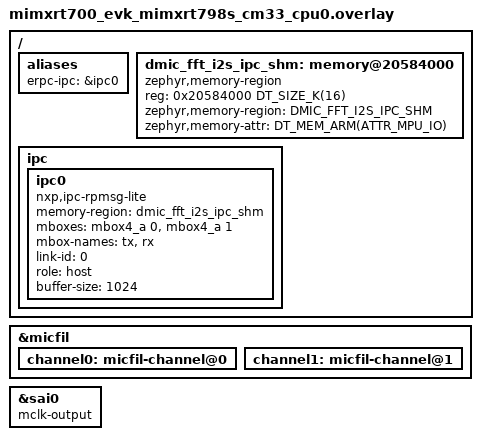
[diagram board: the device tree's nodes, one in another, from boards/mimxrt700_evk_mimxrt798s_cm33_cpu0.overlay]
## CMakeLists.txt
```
# Copyright 2026 NXP
# SPDX-License-Identifier: Apache-2.0

cmake_minimum_required(VERSION 3.20.0)

find_package(Zephyr REQUIRED HINTS $ENV{ZEPHYR_BASE})
project(mpipe_dmic_fft_i2s)

# The HiFi4 computes gain, FFT and IFFT; this core captures and plays back
target_sources(app PRIVATE src/main.c)

include(${CMAKE_CURRENT_LIST_DIR}/dmic_fft_i2s.cmake)

# Boot and image embedding of the HiFi4: the loader of the RTxxx AMP samples
# (dsp.c, dspimgs.S). dspimgs.S includes the reset, text and data sections of
# the HiFi4 image, which are either the prebuilt binaries that sysbuild.cmake
# selected, or the ones of the sysbuild image "remote".
set(RTXXX_DSP_COMMON ${ZEPHYR_BASE}/samples/boards/nxp/adsp/rtxxx/common)

target_sources(app PRIVATE ${RTXXX_DSP_COMMON}/src/dsp.c ${RTXXX_DSP_COMMON}/src/dspimgs.S)
include_directories(${RTXXX_DSP_COMMON}/src)

zephyr_get(HIFI4_BIN_RESET SYSBUILD GLOBAL)
zephyr_get(HIFI4_BIN_TEXT SYSBUILD GLOBAL)
zephyr_get(HIFI4_BIN_DATA SYSBUILD GLOBAL)

if(DEFINED HIFI4_BIN_RESET AND DEFINED HIFI4_BIN_TEXT AND DEFINED HIFI4_BIN_DATA)
  set(hifi4_bin_depends ${HIFI4_BIN_RESET} ${HIFI4_BIN_TEXT} ${HIFI4_BIN_DATA})
else()
  set(hifi4_build_dir ${CMAKE_CURRENT_BINARY_DIR}/../remote/zephyr)
  set(HIFI4_BIN_RESET ${hifi4_build_dir}/zephyr.reset.bin)
  set(HIFI4_BIN_TEXT ${hifi4_build_dir}/zephyr.text.bin)
  set(HIFI4_BIN_DATA ${hifi4_build_dir}/zephyr.data.bin)
  set(hifi4_bin_depends ${hifi4_build_dir}/zephyr.elf)
endif()

set(hifi4_bin_syms
  "HIFI4_BIN_RESET=\"${HIFI4_BIN_RESET}\""
  "HIFI4_BIN_TEXT=\"${HIFI4_BIN_TEXT}\""
  "HIFI4_BIN_DATA=\"${HIFI4_BIN_DATA}\""
)

set_source_files_properties(
  ${RTXXX_DSP_COMMON}/src/dspimgs.S
  PROPERTIES
  COMPILE_DEFINITIONS "${hifi4_bin_syms}"
  OBJECT_DEPENDS "${hifi4_bin_depends}"
)
```

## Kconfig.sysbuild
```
# Copyright 2026 NXP
# SPDX-License-Identifier: Apache-2.0

source "share/sysbuild/Kconfig"

choice DMIC_FFT_I2S_REMOTE
	prompt "HiFi4 image embedded in the Cortex-M33 image"
	default DMIC_FFT_I2S_REMOTE_PREBUILT

config DMIC_FFT_I2S_REMOTE_PREBUILT
	bool "Precompiled HiFi4 binaries"
	help
	  Embed a HiFi4 audio server that was compiled outside of Zephyr.
	  Zephyr does not build it: it only embeds the three section
	  binaries found in DMIC_FFT_I2S_REMOTE_BIN_DIR and loads them on
	  the HiFi4 at boot.

config DMIC_FFT_I2S_REMOTE_ZEPHYR
	bool "Zephyr aud_remote image, built by sysbuild"
	help
	  Build ../aud_remote for the HiFi4 as the sysbuild image "remote".

endchoice

config DMIC_FFT_I2S_REMOTE_BIN_DIR
	string "Directory of the precompiled HiFi4 binaries"
	depends on DMIC_FFT_I2S_REMOTE_PREBUILT
	help
	  Directory with exactly these three raw section images of the
	  HiFi4 server, which sysbuild checks before it embeds them:

	    aud_dsp_server.reset.bin   reset vector, loaded at 0x24020000
	                               (ITCM), at most 1 KiB
	    aud_dsp_server.text.bin    code, loaded at 0x20200000, at most
	                               1 MiB
	    aud_dsp_server.data.bin    data, loaded at 0x20300000, at most
	                               1 MiB

	  Nothing else of that folder is read. The server in these binaries
	  must match this build, sysbuild does not check it:

	  - It is the eRPC server of subsys/mpipe/aud/erpc/
	    mpipe_aud_transform.erpc (interfaces MpipeAudTransform, id 2,
	    and MpipeAudLog, id 3), generated from the same file as the
	    Cortex-M33 client.
	  - It serves the functions gain (1), fft (2) and ifft (3), with
	    four function instances at least.
	  - It is the RPMsg-Lite remote on the 16 KiB shared memory at
	    0x20584000 with MU4 (the Cortex-M33 is the host), with a payload
	    of 1008 bytes per message.
	  - Its audio format and gain are the ones of
	    DMIC_FFT_I2S_SAMPLE_RATE, DMIC_FFT_I2S_FRAME_INTERVAL_US and
	    DMIC_FFT_I2S_GAIN_PERCENT.

	  It must be set when DMIC_FFT_I2S_REMOTE_PREBUILT is selected.

# Audio format and gain. sysbuild.cmake hands them to both images, which
# build them in as DMIC_FFT_I2S_<name> (dmic_fft_i2s.cmake), so that the
# Cortex-M33 and the HiFi4 always agree.

config DMIC_FFT_I2S_SAMPLE_RATE
	int "Sample rate, in Hz"
	default 16000
	help
	  Rate the microphone is captured and the codec played back at. The
	  MICFIL driver only captures at 16000 Hz.

config DMIC_FFT_I2S_FRAME_INTERVAL_US
	int "Duration of one audio block, in microseconds"
	default 16000
	help
	  Each block holds DMIC_FFT_I2S_SAMPLE_RATE x this interval samples,
	  which is also the length of the FFT: that count must be a power of
	  two. The MICFIL driver takes 10000 to 100000 microseconds.

config DMIC_FFT_I2S_GAIN_PERCENT
	int "Gain of each gain stage, in percent"
	default 800
	range 0 10000
	help
	  The HiFi4 scales each sample by this factor before the FFT and
	  again after the inverse FFT, and clamps the result to the 32-bit
	  range each time. The microphone signal is quiet: the default
	  amplifies it by 8 (18 dB) in each stage, 64 (36 dB) in all.
```

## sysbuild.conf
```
# Audio format and gain, given to both the Cortex-M33 and the HiFi4 image
# (see Kconfig.sysbuild for the constraints on each value)

# Sample rate, in Hz: the only one the MICFIL driver captures at
SB_CONFIG_DMIC_FFT_I2S_SAMPLE_RATE=16000

# Duration of one audio block, in microseconds. Rate x interval is the FFT
# length and must be a power of two.
SB_CONFIG_DMIC_FFT_I2S_FRAME_INTERVAL_US=16000

# Gain applied on the HiFi4 before the FFT and again after the inverse FFT,
# in percent
SB_CONFIG_DMIC_FFT_I2S_GAIN_PERCENT=800
```

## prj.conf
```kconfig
CONFIG_LOG=y
CONFIG_MAIN_STACK_SIZE=4096
CONFIG_CACHE_MANAGEMENT=y

CONFIG_MPIPE=y
CONFIG_MPIPE_BASE=y
CONFIG_MPIPE_BASE_CAPS_FILTER=y
CONFIG_MPIPE_BASE_QUEUE=y
# The pipeline thread plus the queue thread
CONFIG_MPIPE_THREADS_NUM=2
CONFIG_MPIPE_AUD=y
CONFIG_MPIPE_PLAYER=y
# Microphone blocks plus the HiFi4 buffers the four stages hold. Not
# measured: 20 was enough for three stages, 4 more for the output gain.
CONFIG_MPIPE_NET_BUF_POOL_COUNT=24

CONFIG_AUDIO_DMIC=y
CONFIG_AUDIO_CODEC=y
CONFIG_I2S=y

# The codec default (0 dB) is loud next to the microphones: start lower
CONFIG_MPIPE_AUD_I2S_CODEC_SINK_SET_OUTPUT_VOLUME=y

# The HiFi4 computes gain, FFT, IFFT and gain: eRPC client over the IPC service
# (RPMsg-Lite on MU4)
CONFIG_MPIPE_RPC=y
CONFIG_MPIPE_ERPC=y

CONFIG_ERPC=y
CONFIG_ERPC_TRANSPORT_IPC_SERVICE=y
CONFIG_ERPC_ALLOCATION_POLICY_STATIC=y
CONFIG_ERPC_CODEC_COUNT=1
# The eRPC port routes operator new to k_malloc, so a heap must exist even
# with static allocation
CONFIG_HEAP_MEM_POOL_SIZE=1024

# Only buffer addresses and formats travel, so the messages stay small. The
# eRPC buffer is the RPMsg-Lite payload, 2^n - 16 bytes: the same value on
# both cores.
CONFIG_ERPC_DEFAULT_BUFFER_SIZE=1008
CONFIG_RL_BUFFER_PAYLOAD_SIZE=1008
CONFIG_RL_USE_STATIC_API=y

# The bus carries end-of-stream and errors, never data: it needs neither
# zbus priority boost nor zbus logging of its own.
CONFIG_ZBUS_PRIORITY_BOOST=n
CONFIG_ZBUS_LOG_LEVEL_ERR=y
```

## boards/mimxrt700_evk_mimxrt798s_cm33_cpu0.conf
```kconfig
# One 16 ms block of 32-bit stereo at 16 kHz is 2048 bytes.
# The MICFIL driver needs DMIC_NXP_MICFIL_QUEUE_SIZE + 2 blocks, the queue
# holds two more and one is in transit.
CONFIG_MPIPE_AUD_BUFFER_POOL_SZ_MAX=2048
CONFIG_MPIPE_AUD_BUFFER_POOL_NUM_MAX=10
```

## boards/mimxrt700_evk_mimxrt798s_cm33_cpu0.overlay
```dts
/*
 * Copyright 2026 NXP
 *
 * SPDX-License-Identifier: Apache-2.0
 */

#include <zephyr/dt-bindings/memory-attr/memory-attr-arm.h>

/ {
	aliases {
		/* The IPC instance eRPC runs over */
		erpc-ipc = &ipc0;
	};

	/*
	 * RPMsg-Lite buffers and vrings shared with the HiFi4. Same address as
	 * sram_shared1 in the HiFi4 devicetree; mapped uncached on this core.
	 */
	dmic_fft_i2s_ipc_shm: memory@20584000 {
		compatible = "zephyr,memory-region", "mmio-sram";
		reg = <0x20584000 DT_SIZE_K(16)>;
		zephyr,memory-region = "DMIC_FFT_I2S_IPC_SHM";
		zephyr,memory-attr = <DT_MEM_ARM(ATTR_MPU_IO)>;
	};

	ipc {
		ipc0: ipc0 {
			compatible = "nxp,ipc-rpmsg-lite";
			memory-region = <&dmic_fft_i2s_ipc_shm>;
			/* MU4 channel 0 rings the HiFi4, channel 1 rings back */
			mboxes = <&mbox4_a 0>, <&mbox4_a 1>;
			mbox-names = "tx", "rx";
			link-id = <0>;
			role = "host";
			buffer-size = <1024>;
			status = "okay";
		};
	};
};

dmic_dev: &micfil {
	status = "okay";

	channel0: micfil-channel@0 {
		status = "okay";
	};

	channel1: micfil-channel@1 {
		status = "okay";
	};
};

/* SAI0 is the clock controller of the link: it also feeds MCLK to the WM8962 */
&sai0 {
	mclk-output;
};
```

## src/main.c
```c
/*
 * Copyright 2026 NXP
 *
 * SPDX-License-Identifier: Apache-2.0
 */

/*
 * Microphone -> gain -> FFT -> IFFT -> gain -> codec, as an mpipe pipeline:
 *
 *   dmic_src -> caps_filter -> queue -> gain -> fft -> ifft -> out_gain -> i2s_sink
 *
 * The HiFi4 computes gain, fft, ifft and out_gain over eRPC: each is an
 * audio transform client that opens its own function on the HiFi4, the two
 * gains each an instance of the same function. The output of each stage
 * comes back to the Cortex-M33, which copies it into a free HiFi4 input
 * buffer for the next one. fft computes one spectrum per microphone
 * channel, and ifft turns them back into the two channels of the codec.
 */

#include <zephyr/kernel.h>
#include <zephyr/logging/log.h>

#include <zephyr/mpipe/mpipe.h>
#include <zephyr/mpipe/aud/mpipe_aud.h>
#include <zephyr/mpipe/aud/mpipe_aud_dmic_src.h>
#include <zephyr/mpipe/aud/mpipe_aud_i2s_codec_sink.h>
#include <zephyr/mpipe/aud/mpipe_aud_src.h>
#include <zephyr/mpipe/aud/mpipe_aud_transform_client_erpc.h>
#include <zephyr/mpipe/base/mpipe_caps_filter.h>
#include <zephyr/mpipe/base/mpipe_queue.h>
#include <zephyr/mpipe/utils/mpipe_player.h>

#include <dsp.h>

LOG_MODULE_REGISTER(main, LOG_LEVEL_INF);

/* Element IDs (values are arbitrary; only uniqueness within the pipeline matters) */
enum {
	PIPE_ID,
	DMIC_SRC_ID,
	CAPS_FILTER_ID,
	QUEUE_ID,
	GAIN_ID,
	FFT_ID,
	IFFT_ID,
	OUT_GAIN_ID,
	I2S_SINK_ID,
};

/* Samples in one block, as the microphone source counts them */
#define BLOCK_SAMPLES                                                                              \
	((uint32_t)(((uint64_t)DMIC_FFT_I2S_SAMPLE_RATE * DMIC_FFT_I2S_FRAME_INTERVAL_US) /        \
		    USEC_PER_SEC))

/* One block of the codec stream: 32-bit stereo */
#define TX_BLOCK_SIZE (BLOCK_SAMPLES * sizeof(int32_t) * 2U)

/*
 * Blocks of the codec stream: the sink primes 3 before it starts, the I2S
 * driver queues CONFIG_I2S_TX_BLOCK_COUNT and its DMA holds the one it plays.
 */
#define TX_BLOCK_COUNT 6U

/*
 * The DMIC source takes its blocks from this slab, as in the dmic_i2s sample.
 * Kept uncached because the audio DMA writes it.
 */
__nocache struct k_mem_slab mem_slab;

/*
 * The I2S sink copies each block from the HiFi4 into this slab: the DMA
 * reads it, so it is uncached too.
 */
K_MEM_SLAB_DEFINE_IN_SECT_STATIC(tx_slab, __nocache, TX_BLOCK_SIZE, TX_BLOCK_COUNT, 32);

static struct mpipe pipe;
static struct mpipe_aud_dmic_src dmic_src;
static struct mpipe_caps_filter caps_filter;
static struct mpipe_queue queue;
static struct mpipe_aud_transform_client gain;
static struct mpipe_aud_transform_client fft;
static struct mpipe_aud_transform_client ifft;
static struct mpipe_aud_transform_client out_gain;
static struct mpipe_aud_i2s_codec_sink i2s_sink;
static struct mpipe_player player;

int main(void)
{
	uint8_t queue_size = 2U;
	enum mpipe_base_queue_leak queue_leak = MPIPE_BASE_QUEUE_LEAK_OLDEST;
	struct mpipe_structure caps;
	int ret;

	ret = mpipe_pipeline_init(&pipe, PIPE_ID);
	if (ret != 0) {
		goto err;
	}

	ret = mpipe_aud_dmic_src_init(&dmic_src, DMIC_SRC_ID);
	if (ret != 0) {
		goto err;
	}

	ret = mpipe_object_set_properties((struct mpipe_object *)&dmic_src,
					  MPIPE_PROP_AUD_SRC_SLAB_PTR, &mem_slab,
					  MPIPE_PROP_LIST_END);
	if (ret != 0) {
		goto err;
	}

	ret = mpipe_caps_filter_init(&caps_filter, CAPS_FILTER_ID);
	if (ret != 0) {
		goto err;
	}

	/*
	 * The PCM format the HiFi4 takes: 32-bit, the only width the MICFIL
	 * driver produces, the two microphones interleaved. The DMIC_FFT_I2S_*
	 * values come from dmic_fft_i2s.cmake, set by sysbuild for both images.
	 */
	ret = mpipe_structure_init_fields(&caps, MPIPE_MEDIA_AUDIO_PCM, MPIPE_CAPS_SAMPLE_RATE,
					  MPIPE_TYPE_UINT, DMIC_FFT_I2S_SAMPLE_RATE,
					  MPIPE_CAPS_BIT_WIDTH, MPIPE_TYPE_UINT, 32U,
					  MPIPE_CAPS_NUM_CHANNELS, MPIPE_TYPE_UINT, 2U,
					  MPIPE_CAPS_FRAME_INTERVAL, MPIPE_TYPE_UINT,
					  DMIC_FFT_I2S_FRAME_INTERVAL_US, MPIPE_CAPS_END);
	if (ret != 0) {
		goto err;
	}

	ret = mpipe_object_set_properties((struct mpipe_object *)&caps_filter,
					  MPIPE_PROP_BASE_CAPS_FILTER_CAPS, &caps,
					  MPIPE_PROP_LIST_END);
	if (ret != 0) {
		goto err;
	}

	/*
	 * The queue runs the HiFi4 stages and the playback on a thread of
	 * their own. When they fall behind, it drops the oldest block instead
	 * of holding the capture: MICFIL stops when it runs out of blocks.
	 */
	ret = mpipe_queue_init(&queue, QUEUE_ID);
	if (ret != 0) {
		goto err;
	}

	ret = mpipe_object_set_properties((struct mpipe_object *)&queue,
					  MPIPE_PROP_BASE_QUEUE_SIZE, &queue_size,
					  MPIPE_PROP_BASE_QUEUE_LEAK, &queue_leak,
					  MPIPE_PROP_LIST_END);
	if (ret != 0) {
		goto err;
	}

	ret = mpipe_aud_i2s_codec_sink_init(&i2s_sink, I2S_SINK_ID);
	if (ret != 0) {
		goto err;
	}

	ret = mpipe_object_set_properties((struct mpipe_object *)&i2s_sink,
					  MPIPE_PROP_AUD_SINK_SLAB_PTR, &tx_slab,
					  MPIPE_PROP_LIST_END);
	if (ret != 0) {
		goto err;
	}

	ret = mpipe_bin_add((struct mpipe_bin *)&pipe, (struct mpipe_element *)&dmic_src,
			    (struct mpipe_element *)&caps_filter, (struct mpipe_element *)&queue,
			    (struct mpipe_element *)&i2s_sink, NULL);
	if (ret != 0) {
		LOG_ERR("Failed to add elements (%d)", ret);
		goto err;
	}

	ret = mpipe_element_link((struct mpipe_element *)&dmic_src,
				 (struct mpipe_element *)&caps_filter,
				 (struct mpipe_element *)&queue, NULL);
	if (ret != 0) {
		LOG_ERR("Failed to link elements (%d)", ret);
		goto err;
	}

	/* The HiFi4 stages, between the queue and the codec */
	dsp_start();

	/*
	 * The first element brings up eRPC: the HiFi4 answers once booted.
	 * Each element opens its own function on the HiFi4 and asks for the
	 * buffers of that instance.
	 */
	ret = mpipe_aud_transform_client_erpc_init(&gain, GAIN_ID, MPIPE_AUD_REMOTE_FUNC_GAIN);
	if (ret != 0) {
		LOG_ERR("HiFi4 did not answer (%d)", ret);
		goto err;
	}

	LOG_INF("HiFi4 ready");

	ret = mpipe_aud_transform_client_erpc_init(&fft, FFT_ID, MPIPE_AUD_REMOTE_FUNC_FFT);
	if (ret != 0) {
		LOG_ERR("HiFi4 refused the FFT (%d)", ret);
		goto err;
	}

	ret = mpipe_aud_transform_client_erpc_init(&ifft, IFFT_ID, MPIPE_AUD_REMOTE_FUNC_IFFT);
	if (ret != 0) {
		LOG_ERR("HiFi4 refused the IFFT (%d)", ret);
		goto err;
	}

	/* A second instance of the gain function, with the same gain */
	ret = mpipe_aud_transform_client_erpc_init(&out_gain, OUT_GAIN_ID,
						   MPIPE_AUD_REMOTE_FUNC_GAIN);
	if (ret != 0) {
		LOG_ERR("HiFi4 refused the output gain (%d)", ret);
		goto err;
	}

	LOG_INF("Gain, FFT, IFFT and gain computed on HiFi4");

	ret = mpipe_bin_add((struct mpipe_bin *)&pipe, (struct mpipe_element *)&gain,
			    (struct mpipe_element *)&fft, (struct mpipe_element *)&ifft,
			    (struct mpipe_element *)&out_gain, NULL);
	if (ret != 0) {
		LOG_ERR("Failed to add the HiFi4 stages (%d)", ret);
		goto err;
	}

	ret = mpipe_element_link((struct mpipe_element *)&queue, (struct mpipe_element *)&gain,
				 (struct mpipe_element *)&fft, (struct mpipe_element *)&ifft,
				 (struct mpipe_element *)&out_gain,
				 (struct mpipe_element *)&i2s_sink, NULL);
	if (ret != 0) {
		LOG_ERR("Failed to link the HiFi4 stages (%d)", ret);
		goto err;
	}

	ret = mpipe_player_init(&player, &pipe);
	if (ret != 0) {
		LOG_ERR("Failed to init player (%d)", ret);
		goto err;
	}

	LOG_INF("Loopback started");

	(void)mpipe_player_play(&player);
	(void)mpipe_player_wait_quit(&player);
	(void)mpipe_player_deinit(&player);

	return 0;

err:
	LOG_ERR("Aborting sample (%d)", ret);

	return 0;
}
```
